AUTOSAR XML (schema 00048)
package /AUTOLIV/SoftwareComponents/BSR
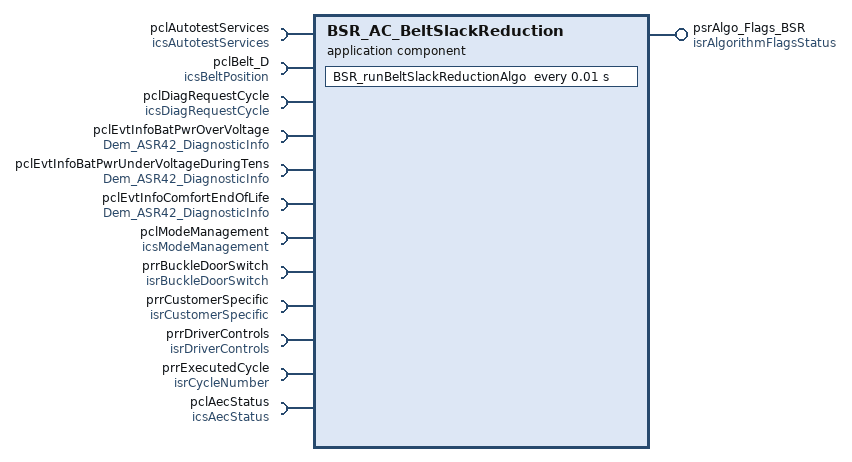
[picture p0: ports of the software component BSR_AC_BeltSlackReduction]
  application sw component type BSR_AC_BeltSlackReduction
    11 x require port:
      pclAutotestServices: required-com-specs=[GetLastCriticalAutotestID, GetTestResult], required-interface=icsAutotestServices
      pclBelt_D: required-com-specs=[GetFromMinPos_deg, GetFromMinPos_mm, GetFromT0_deg, GetFromT0_mm, GetRange_deg, GetRange_mm], required-interface=icsBeltPosition
      pclDiagRequestCycle: required-com-specs=[ClearDiagRequestCycle, GetDiagRequestCycle], required-interface=icsDiagRequestCycle
      pclEvtInfoBatPwrOverVoltage: required-interface=Dem_ASR42_DiagnosticInfo
        required-com-specs:
          GetDTCOfEvent
          GetDebouncingOfEvent
          GetEventExtendedDataRecord
          GetEventExtendedDataRecordEx
          GetEventFailed
          GetEventFreezeFrameData
          GetEventFreezeFrameDataEx
          GetEventStatus
          GetEventTested
          GetFaultDetectionCounter
      pclEvtInfoBatPwrUnderVoltageDuringTens: required-interface=Dem_ASR42_DiagnosticInfo
        required-com-specs:
          GetDTCOfEvent
          GetDebouncingOfEvent
          GetEventExtendedDataRecord
          GetEventExtendedDataRecordEx
          GetEventFailed
          GetEventFreezeFrameData
          GetEventFreezeFrameDataEx
          GetEventStatus
          GetEventTested
          GetFaultDetectionCounter
      pclEvtInfoComfortEndOfLife: required-interface=Dem_ASR42_DiagnosticInfo
        required-com-specs:
          GetDTCOfEvent
          GetDebouncingOfEvent
          GetEventExtendedDataRecord
          GetEventExtendedDataRecordEx
          GetEventFailed
          GetEventFreezeFrameData
          GetEventFreezeFrameDataEx
          GetEventStatus
          GetEventTested
          GetFaultDetectionCounter
      pclModeManagement: client-com-spec=CheckModeStatus, required-interface=icsModeManagement
      prrBuckleDoorSwitch: required-interface=isrBuckleDoorSwitch
        required-com-specs:
          data-element=u8BuckleSwitch, init-value=constant-reference=APPLINIT_KU8_BUCKLE_SWITCH_STATUS_NOT_DEFINED
          data-element=u8DoorSwitch, init-value=constant-reference=APPLINIT_KU8_DOOR_SWITCH_STATUS_NOT_DEFINED
      prrCustomerSpecific: required-interface=isrCustomerSpecific
        required-com-specs:
          data-element=b8HardReleaseRequest
          data-element=b8IsCarCrankingActive, init-value=constant-reference=APPLINIT_KB8_CAR_CRANKING_ACTIVE_TRUE
          data-element=b8IsCarCrashDetected, init-value=constant-reference=APPLINIT_KB8_CAR_CRASH_DETECTED_FALSE
          data-element=b8IsTrigOffEventAllowed
          data-element=b8PreCrashRequestEnable, init-value=constant-reference=APPLINIT_KB8_BOOLEAN_FALSE
          data-element=u8BeltSlackStatus, init-value=constant-reference=APPLINIT_KU8_BELT_SLACK_STATUS_NOT_DEFINED
          data-element=u8HapticRequest, init-value=constant-reference=APPLINIT_KU8_HAPTIC_REQUEST_NO
          data-element=u8PreCrashRequest, init-value=constant-reference=APPLINIT_KU8_PRE_CRASH_REQUEST_NO_REQUEST
          data-element=u8TriggerRequest
          data-element=b8SignalRelInhibition
      prrDriverControls: required-interface=isrDriverControls
        required-com-specs:
          data-element=b8VehicleMovingBackwards, init-value=constant-reference=APPLINIT_KB8_BOOLEAN_FALSE
          data-element=s16AccelerationPedalPositionRate, init-value=constant-reference=APPLINIT_KS16_ACCEL_PEDAL_POS_RATE_ZERO
          data-element=s16BrakePressureRate, init-value=constant-reference=APPLINIT_KS16_BRAKE_PRESSURE_RATE_ZERO
          data-element=s16HWAngle, init-value=constant-reference=APPLINIT_KS16_HW_ANGLE_ZERO
          data-element=s16HWRate, init-value=constant-reference=APPLINIT_KS16_HW_RATE_ZERO
          data-element=u16BrakePressure, init-value=constant-reference=APPLINIT_KU16_BRAKE_PRESSURE_ZERO
          data-element=u16VehicleSpeed, init-value=constant-reference=APPLINIT_KU16_VEHICLE_SPEED_ZERO
          data-element=u8AccelerationPedalPosition, init-value=constant-reference=APPLINIT_KU8_ACCEL_PEDAL_POS_ZERO
          data-element=u8KlemmenStatus, init-value=constant-reference=APPLINIT_KU8_KLEMMEN_STATUS_ZERO
      prrExecutedCycle: nonqueued-receiver-com-spec{data-element=u8CycleNumber, init-value=constant-reference=APPLINIT_KU8_CYCLE_NUMBER_NONE}, required-interface=isrCycleNumber
    provide port psrAlgo_Flags_BSR: provided-interface=isrAlgorithmFlagsStatus
      provided-com-specs:
        data-element=b8InterruptFlag, init-value=constant-reference=APPLINIT_KB8_ALGO_FLAG_FALSE
        data-element=b8PreActivationFlag, init-value=constant-reference=APPLINIT_KB8_ALGO_FLAG_FALSE
        data-element=b8PreConditionsFlag, init-value=constant-reference=APPLINIT_KB8_ALGO_FLAG_FALSE
        data-element=b8TriggerFlag, init-value=constant-reference=APPLINIT_KB8_ALGO_FLAG_FALSE
        data-element=u8TriggeringSource, init-value=constant-reference=APPLINIT_KU8_TRIGGERING_SOURCE_NO
    require port pclAecStatus: required-interface=icsAecStatus
      required-com-specs:
        SetAecEvent
        GetNumberOfImplementedAec
        GetAecStatus
        GetAecQualificationCount
        GetAecNvpBlockRecordingStatus
        GetAecGroupsStatus
        GetAecDeskillThrs
    behavior BSR_IB_BeltSlackReduction: data-type-mapping=DataTypeMappingSet_PP4G
      timing event BSR_evBeltSlackReductionAlgo: start-on-event=BSR_runBeltSlackReductionAlgo, period=0.01  # Periodical event to trig BSR runnable
      runnable BSR_runBeltSlackReductionAlgo
        data-receive-point-by-arguments:
          5 x access:
            DRP_prrBuckleDoorSwitch_u8BuckleSwitch: accessed-variable=prrBuckleDoorSwitch.u8BuckleSwitch
            DRP_prrCustomerSpecific_b8IsCarCrashDetected: accessed-variable=prrCustomerSpecific.b8IsCarCrashDetected
            DRP_prrCustomerSpecific_u8BeltSlackStatus: accessed-variable=prrCustomerSpecific.u8BeltSlackStatus
            DRP_prrDriverControls_u16VehicleSpeed: accessed-variable=prrDriverControls.u16VehicleSpeed
            DRP_prrExecutedCycle_u8CycleNumber: accessed-variable=prrExecutedCycle.u8CycleNumber
        data-send-points:
          5 x access:
            DSP_psrAlgo_Flags_BSR_b8InterruptFlag: accessed-variable=psrAlgo_Flags_BSR.b8InterruptFlag
            DSP_psrAlgo_Flags_BSR_b8PreActivationFlag: accessed-variable=psrAlgo_Flags_BSR.b8PreActivationFlag
            DSP_psrAlgo_Flags_BSR_b8PreConditionsFlag: accessed-variable=psrAlgo_Flags_BSR.b8PreConditionsFlag
            DSP_psrAlgo_Flags_BSR_b8TriggerFlag: accessed-variable=psrAlgo_Flags_BSR.b8TriggerFlag
            DSP_psrAlgo_Flags_BSR_u8TriggeringSource: accessed-variable=psrAlgo_Flags_BSR.u8TriggeringSource
        9 x sync call:
          SSCP_pclBelt_D_GetFromT0_deg: operation=pclBelt_D.GetFromT0_deg
          SSCP_pclDiagRequestCycle_ClearDiagRequestCycle: operation=pclDiagRequestCycle.ClearDiagRequestCycle
          SSCP_pclDiagRequestCycle_GetDiagRequestCycle: operation=pclDiagRequestCycle.GetDiagRequestCycle
          SSCP_pclModeManagement_CheckModeStatus: operation=pclModeManagement.CheckModeStatus
          SSCP_pclTestResult_GetTestResult: operation=pclAutotestServices.GetTestResult
          scp_GetEventStatus: operation=pclEvtInfoComfortEndOfLife.GetEventStatus
          scp_GetEventStatus1: operation=pclEvtInfoBatPwrOverVoltage.GetEventStatus
          scp_GetEventStatus2: operation=pclEvtInfoBatPwrUnderVoltageDuringTens.GetEventStatus
          SC_pclAecStatus_GetAecStatus: operation=pclAecStatus.GetAecStatus
  swc implementation BSR_impBeltSlackReduction: behavior=BSR_IB_BeltSlackReduction
    code-descriptors:
      code BSR_Impl_Code: artifact-descriptors=autosar-engineering-object=category=SWSRC
